# BL602 register map
Vendor: bouffalolab; Series: WiFi BT
Registers are 32-bit, read-write, reset 0x0 unless marked. A register's access mark holds for its fields unless they carry their own. Offsets are from the block's base; [hi:lo] are bit positions; {n}, {i} and the like mark numbered series.

## SEC_ENG
Base 0x40004000
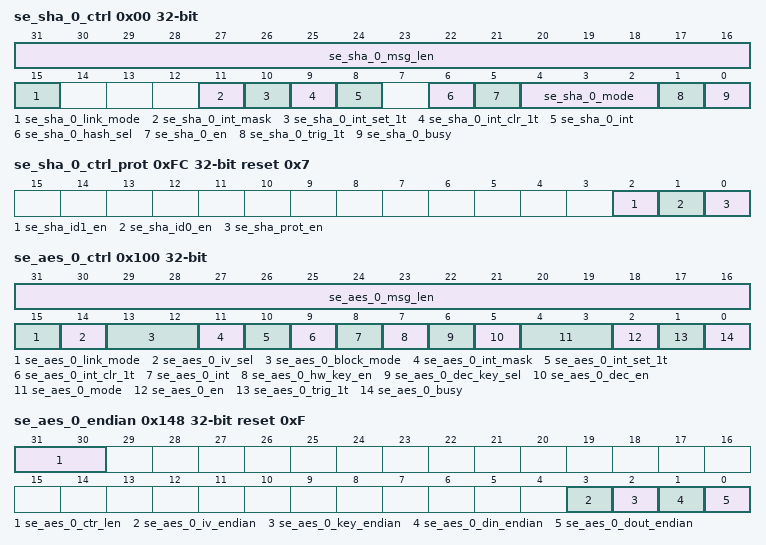
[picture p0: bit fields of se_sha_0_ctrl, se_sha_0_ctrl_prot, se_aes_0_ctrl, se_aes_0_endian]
0x00 se_sha_0_ctrl
  [31:16] se_sha_0_msg_len, [15] se_sha_0_link_mode, [11] se_sha_0_int_mask, [10] se_sha_0_int_set_1t, [9] se_sha_0_int_clr_1t, [8] se_sha_0_int ro, [6] se_sha_0_hash_sel, [5] se_sha_0_en, [4:2] se_sha_0_mode, [1] se_sha_0_trig_1t, [0] se_sha_0_busy ro
0x04 se_sha_0_msa
0x08 se_sha_0_status ro reset 0x41
0x0C se_sha_0_endian reset 0x1
  [0] se_sha_0_dout_endian
{0x10+4i} se_sha_0_hash_l_{i} ro (i=0..7)
{0x30+4i} se_sha_0_hash_h_{i} ro (i=0..7)
0x50 se_sha_0_link
  [31:0] se_sha_0_lca
0xFC se_sha_0_ctrl_prot reset 0x7
  [2] se_sha_id1_en, [1] se_sha_id0_en, [0] se_sha_prot_en
0x100 se_aes_0_ctrl
  [31:16] se_aes_0_msg_len, [15] se_aes_0_link_mode, [14] se_aes_0_iv_sel, [13:12] se_aes_0_block_mode, [11] se_aes_0_int_mask, [10] se_aes_0_int_set_1t, [9] se_aes_0_int_clr_1t, [8] se_aes_0_int ro, [7] se_aes_0_hw_key_en, [6] se_aes_0_dec_key_sel, [5] se_aes_0_dec_en, [4:3] se_aes_0_mode, [2] se_aes_0_en, [1] se_aes_0_trig_1t, [0] se_aes_0_busy ro
0x104 se_aes_0_msa
0x108 se_aes_0_mda
0x10C se_aes_0_status ro reset 0x100
{0x110+4i} se_aes_0_iv_{i} (i=0..3)
{0x120+4i} se_aes_0_key_{i} (i=0..7)
0x140 se_aes_0_key_sel_0
  [1:0] se_aes_0_key_sel_0
0x144 se_aes_0_key_sel_1
  [1:0] se_aes_0_key_sel_1
0x148 se_aes_0_endian reset 0xF
  [31:30] se_aes_0_ctr_len, [3] se_aes_0_iv_endian, [2] se_aes_0_key_endian, [1] se_aes_0_din_endian, [0] se_aes_0_dout_endian
0x14C se_aes_0_sboot
  [0] se_aes_0_sboot_key_sel
0x150 se_aes_0_link
  [31:0] se_aes_0_lca
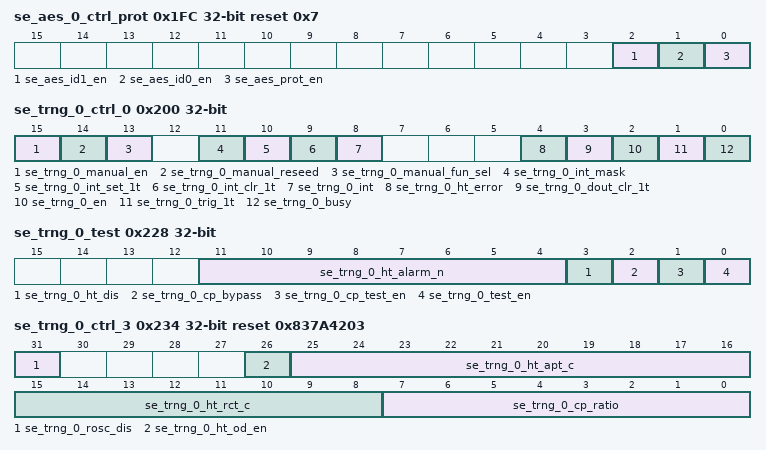
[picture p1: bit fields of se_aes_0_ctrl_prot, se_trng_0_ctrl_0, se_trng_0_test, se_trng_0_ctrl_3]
0x1FC se_aes_0_ctrl_prot reset 0x7
  [2] se_aes_id1_en, [1] se_aes_id0_en, [0] se_aes_prot_en
0x200 se_trng_0_ctrl_0
  [15] se_trng_0_manual_en, [14] se_trng_0_manual_reseed, [13] se_trng_0_manual_fun_sel, [11] se_trng_0_int_mask, [10] se_trng_0_int_set_1t, [9] se_trng_0_int_clr_1t, [8] se_trng_0_int ro, [4] se_trng_0_ht_error ro, [3] se_trng_0_dout_clr_1t, [2] se_trng_0_en, [1] se_trng_0_trig_1t, [0] se_trng_0_busy ro
0x204 se_trng_0_status ro reset 0x100020
{0x208+4i} se_trng_0_dout_{i} ro (i=0..7)
0x228 se_trng_0_test
  [11:4] se_trng_0_ht_alarm_n, [3] se_trng_0_ht_dis, [2] se_trng_0_cp_bypass, [1] se_trng_0_cp_test_en, [0] se_trng_0_test_en
0x22C se_trng_0_ctrl_1 reset 0xFFFF
  [31:0] se_trng_0_reseed_n_lsb
0x230 se_trng_0_ctrl_2 reset 0xFF
  [15:0] se_trng_0_reseed_n_msb
0x234 se_trng_0_ctrl_3 reset 0x837A4203
  [31] se_trng_0_rosc_dis — Used to be called 'se_trng_0_rosc_en', but the SDK calls it 'se_trng_0_rosc_dis'.
  [26] se_trng_0_ht_od_en
  [25:16] se_trng_0_ht_apt_c
  [15:8] se_trng_0_ht_rct_c
  [7:0] se_trng_0_cp_ratio
{0x240+4i} se_trng_0_test_out_{i} ro (i=0..3)
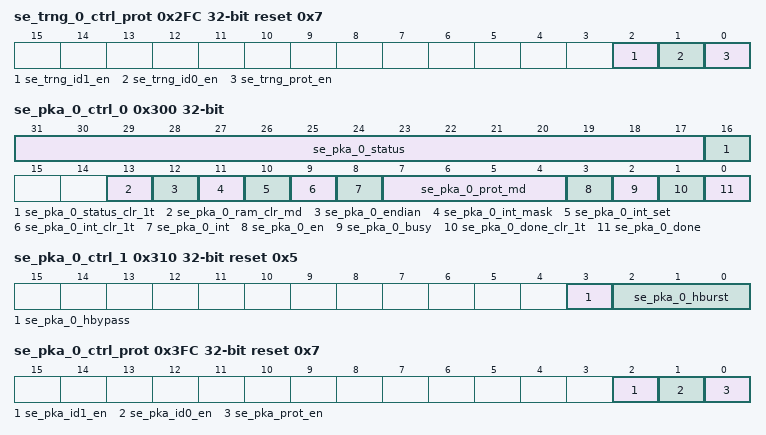
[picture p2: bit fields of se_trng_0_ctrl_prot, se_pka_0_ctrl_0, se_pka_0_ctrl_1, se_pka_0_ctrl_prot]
0x2FC se_trng_0_ctrl_prot reset 0x7
  [2] se_trng_id1_en, [1] se_trng_id0_en, [0] se_trng_prot_en
0x300 se_pka_0_ctrl_0
  [31:17] se_pka_0_status ro, [16] se_pka_0_status_clr_1t, [13] se_pka_0_ram_clr_md, [12] se_pka_0_endian, [11] se_pka_0_int_mask, [10] se_pka_0_int_set, [9] se_pka_0_int_clr_1t, [8] se_pka_0_int ro, [7:4] se_pka_0_prot_md, [3] se_pka_0_en, [2] se_pka_0_busy ro, [1] se_pka_0_done_clr_1t, [0] se_pka_0_done ro
0x30C se_pka_0_seed
0x310 se_pka_0_ctrl_1 reset 0x5
  [3] se_pka_0_hbypass, [2:0] se_pka_0_hburst
0x340 se_pka_0_rw
0x360 se_pka_0_rw_burst
0x3FC se_pka_0_ctrl_prot reset 0x7
  [2] se_pka_id1_en, [1] se_pka_id0_en, [0] se_pka_prot_en
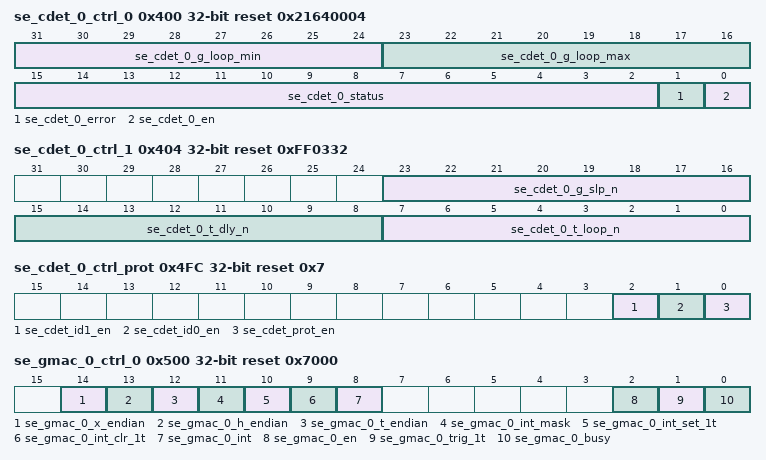
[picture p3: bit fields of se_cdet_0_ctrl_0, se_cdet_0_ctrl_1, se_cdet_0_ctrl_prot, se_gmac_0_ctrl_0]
0x400 se_cdet_0_ctrl_0 reset 0x21640004
  [31:24] se_cdet_0_g_loop_min, [23:16] se_cdet_0_g_loop_max, [15:2] se_cdet_0_status ro, [1] se_cdet_0_error ro, [0] se_cdet_0_en
0x404 se_cdet_0_ctrl_1 reset 0xFF0332
  [23:16] se_cdet_0_g_slp_n, [15:8] se_cdet_0_t_dly_n, [7:0] se_cdet_0_t_loop_n
0x4FC se_cdet_0_ctrl_prot reset 0x7
  [2] se_cdet_id1_en, [1] se_cdet_id0_en, [0] se_cdet_prot_en
0x500 se_gmac_0_ctrl_0 reset 0x7000
  [14] se_gmac_0_x_endian, [13] se_gmac_0_h_endian, [12] se_gmac_0_t_endian, [11] se_gmac_0_int_mask, [10] se_gmac_0_int_set_1t, [9] se_gmac_0_int_clr_1t, [8] se_gmac_0_int ro, [2] se_gmac_0_en, [1] se_gmac_0_trig_1t, [0] se_gmac_0_busy ro
0x504 se_gmac_0_lca
0x508 se_gmac_0_status ro reset 0xF1000000
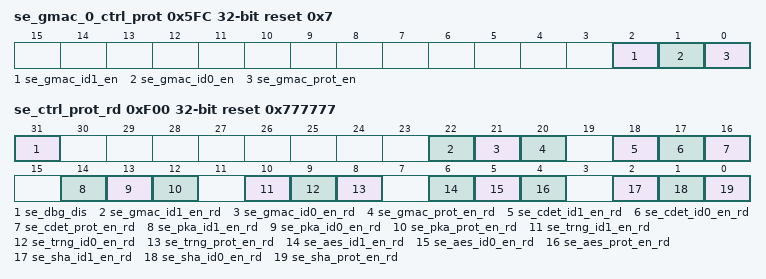
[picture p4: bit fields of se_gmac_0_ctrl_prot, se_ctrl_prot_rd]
0x5FC se_gmac_0_ctrl_prot reset 0x7
  [2] se_gmac_id1_en, [1] se_gmac_id0_en, [0] se_gmac_prot_en
0xF00 se_ctrl_prot_rd ro reset 0x777777
  [31] se_dbg_dis, [22] se_gmac_id1_en_rd, [21] se_gmac_id0_en_rd, [20] se_gmac_prot_en_rd, [18] se_cdet_id1_en_rd, [17] se_cdet_id0_en_rd, [16] se_cdet_prot_en_rd, [14] se_pka_id1_en_rd, [13] se_pka_id0_en_rd, [12] se_pka_prot_en_rd, [10] se_trng_id1_en_rd, [9] se_trng_id0_en_rd, [8] se_trng_prot_en_rd, [6] se_aes_id1_en_rd, [5] se_aes_id0_en_rd, [4] se_aes_prot_en_rd, [2] se_sha_id1_en_rd, [1] se_sha_id0_en_rd, [0] se_sha_prot_en_rd
{0xF04+4i} se_ctrl_reserved_{i} (i=0..2)
